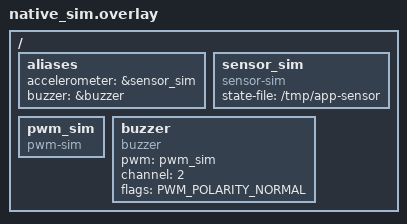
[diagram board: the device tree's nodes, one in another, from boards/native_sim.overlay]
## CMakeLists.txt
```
cmake_minimum_required(VERSION 3.20.0)

find_package(Zephyr REQUIRED HINTS $ENV{ZEPHYR_BASE})
project(workshop)

target_include_directories(app PRIVATE ${CMAKE_CURRENT_SOURCE_DIR}/src)

target_sources(app PRIVATE
    src/cpp_wrappers/ApplicationAssert.cpp
    src/drivers/buzzer.c
    src/frequency.c
    src/SensorReader.cpp
    src/BuzzerController.cpp
    src/main.cpp
)

if(CONFIG_ARCH_POSIX)
    target_sources(app PRIVATE 
        src/drivers/sensor_sim.c
        src/drivers/pwm_sim.c
    )
endif()
```

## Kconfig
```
menu "Application"

config APP_HELLO_WORLD_MSG
	string "Hello World Message"
	default "Hello World!"
	help
	  Customizable hello world message.

endmenu

source "Kconfig.zephyr"
```

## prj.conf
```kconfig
CONFIG_DEBUG=y
CONFIG_DEBUG_THREAD_INFO=y
#CONFIG_NO_OPTIMIZATIONS=y

CONFIG_LOG=y
CONFIG_LOG_MODE_DEFERRED=y
#CONFIG_LOG_MODE_IMMEDIATE=y

CONFIG_SHELL=y

CONFIG_I2C=y
#CONFIG_I2C_LOG_LEVEL_DBG=y
#CONFIG_I2C_DUMP_MESSAGES=y

CONFIG_SENSOR=y
CONFIG_SENSOR_SHELL=y
CONFIG_SENSOR_INFO=y
#CONFIG_SENSOR_LOG_LEVEL_DBG=y

CONFIG_PWM=y
CONFIG_PWM_SHELL=y
```

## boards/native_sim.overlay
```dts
#include <zephyr/dt-bindings/pwm/pwm.h>

/ {
	aliases {
		accelerometer = &sensor_sim;
		buzzer = &buzzer;
	};

	sensor_sim: sensor_sim {
		compatible = "sensor-sim";
		state-file = "/tmp/app-sensor";
		status = "okay";
	};

	pwm_sim: pwm_sim {
		compatible = "pwm-sim";
		status = "okay";
	};

	buzzer: buzzer {
		compatible = "buzzer";
		pwm = <&pwm_sim>;
		channel = <2>;
		flags = <PWM_POLARITY_NORMAL>;
		status = "okay";
	};
};
```

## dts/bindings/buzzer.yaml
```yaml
description: |
  Demonstration of a simple driver to control a buzzer.

compatible: "buzzer"

properties:
  pwm:
    type: phandle
    required: true
    description: |
      PWM to be used for the buzzer.
  
  channel:
    type: int
    required: true

  flags:
    type: int
    required: true
```

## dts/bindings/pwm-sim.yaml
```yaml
description: |
  Simulated PWM output.

compatible: "pwm-sim"
```

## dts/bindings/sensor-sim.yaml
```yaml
description: |
  Simulated sensor.

compatible: "sensor-sim"

properties:
  state-file:
    type: string
    required: true
```

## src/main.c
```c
#include <zephyr/kernel.h>
#include <zephyr/logging/log.h>
#include <zephyr/drivers/sensor.h>
#include "drivers/buzzer.h"
#include "frequency.h"

#define PWM_CHANNEL 2

LOG_MODULE_REGISTER(main);

static void sensor_timer_callback(struct k_timer *timer);
static void sensor_thread_function(void *p1, void *p2, void *p3);
static void buzzer_thread_function(void *p1, void *p2, void *p3);

K_TIMER_DEFINE(sensor_timer, sensor_timer_callback, NULL);
K_SEM_DEFINE(sensor_sem, 0, 1);
K_THREAD_DEFINE(sensor_thread, 1024, sensor_thread_function, NULL, NULL, NULL, 5, 0, 0);
K_MSGQ_DEFINE(message_queue, sizeof(struct sensor_value), 3, 1);
K_THREAD_DEFINE(buzzer_thread, 1024, buzzer_thread_function, NULL, NULL, NULL, 5, 0, 0);

int main(void)
{
    LOG_INF("%s %s", CONFIG_APP_HELLO_WORLD_MSG, CONFIG_BOARD_TARGET);

    k_timer_start(&sensor_timer, K_MSEC(20), K_MSEC(20));

    return 0;
}

static void sensor_timer_callback(struct k_timer *timer)
{
    ARG_UNUSED(timer);

    k_sem_give(&sensor_sem);
}

static void sensor_thread_function(void *p1, void *p2, void *p3)
{
    ARG_UNUSED(p1);
    ARG_UNUSED(p2);
    ARG_UNUSED(p3);

    const struct device* sensor_dev = DEVICE_DT_GET(DT_ALIAS(accelerometer));
    struct sensor_value accel_z;
    int ret = 0;

    while (true) {
        k_sem_take(&sensor_sem, K_FOREVER);

        ret = sensor_sample_fetch(sensor_dev);

        if (ret != 0) {
            LOG_ERR("sensor_sample_fetch: %d", ret);
            continue;
        }

        ret = sensor_channel_get(sensor_dev, SENSOR_CHAN_ACCEL_Z, &accel_z);

        if (ret != 0) {
            LOG_ERR("sensor_channel_get: %d", ret);
            continue;
        }

        ret = k_msgq_put(&message_queue, &accel_z, K_NO_WAIT);

        if (ret != 0) {
            LOG_WRN("k_msgq_put: %d", ret);
        }
    }
}

static void buzzer_thread_function(void *p1, void *p2, void *p3)
{
    ARG_UNUSED(p1);
    ARG_UNUSED(p2);
    ARG_UNUSED(p3);

    const struct device* buzzer_dev = DEVICE_DT_GET(DT_ALIAS(buzzer));
    struct sensor_value accel_z;
    int ret = 0;

    while (true) {
        ret = k_msgq_get(&message_queue, &accel_z, K_FOREVER);

        if (ret != 0) {
            LOG_ERR("k_msgq_get: %d", ret);
            continue;
        }

        const float value = sensor_value_to_float(&accel_z);
        const uint32_t freq = accel_to_freq(value);

        if (freq == 0) {
            ret = buzzer_disable(buzzer_dev);
        } else {
            ret = buzzer_enable(buzzer_dev, freq);
        }

        if (ret != 0) {
            LOG_ERR("pwm_set: %d", ret);
        }
    }
}
```

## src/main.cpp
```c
#include "cpp_wrappers/Buzzer.hpp"
#include "cpp_wrappers/Accelerometer.hpp"
#include "cpp_wrappers/Thread.hpp"
#include "cpp_wrappers/SoftwareTimer.hpp"
#include "cpp_wrappers/MessageQueue.hpp"
#include "cpp_wrappers/Semaphore.hpp"
#include <zephyr/logging/log.h>
#include "frequency.h"

#define PWM_CHANNEL 2

LOG_MODULE_REGISTER(main);

static void sensor_timer_callback();
static void sensor_thread_function();
static void buzzer_thread_function();

K_THREAD_STACK_DEFINE(sensor_thread_stack, 1024);
K_THREAD_STACK_DEFINE(buzzer_thread_stack, 1024);

static Thread sensor_thread(sensor_thread_stack, K_THREAD_STACK_SIZEOF(sensor_thread_stack), sensor_thread_function, 5);
static Thread buzzer_thread(buzzer_thread_stack, K_THREAD_STACK_SIZEOF(buzzer_thread_stack), buzzer_thread_function, 5);

static SoftwareTimer sensor_timer(sensor_timer_callback);
static Semaphore sensor_sem(0, 1);
static MessageQueue<float, 3> message_queue;

static Accelerometer accelerometer(DEVICE_DT_GET(DT_ALIAS(accelerometer)));
static Buzzer buzzer(DEVICE_DT_GET(DT_ALIAS(buzzer)));

extern "C" int main(void)
{
    LOG_INF("%s %s", CONFIG_APP_HELLO_WORLD_MSG, CONFIG_BOARD_TARGET);

    sensor_thread.start();
    buzzer_thread.start();

    sensor_timer.start(std::chrono::milliseconds(20));

    return 0;
}

static void sensor_timer_callback()
{
    sensor_sem.give();
}

static void sensor_thread_function()
{
    while (true) {
        sensor_sem.take();
        const float value = accelerometer.read();
        message_queue.put(value);
    }
}

static void buzzer_thread_function()
{
    while (true) {
        const float value = message_queue.get();
        const uint32_t freq = accel_to_freq(value);

        if (freq == 0) {
            buzzer.disable();
        } else {
            buzzer.enable(freq);
        }
    }
}
```

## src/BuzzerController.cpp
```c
#include "BuzzerController.hpp"
#include "frequency.h"

BuzzerController::BuzzerController(Thread &thread, 
                                   MessageQueue<float> &message_queue, 
                                   IBuzzer &buzzer) :
    _thread(thread),
    _message_queue(message_queue),
    _buzzer(buzzer)
{
}

void BuzzerController::start()
{
    _thread.start([this] { thread_main(); });
}

void BuzzerController::thread_main()
{
    while (true) {
        const float value = _message_queue.get();
        const uint32_t freq = accel_to_freq(value);

        if (freq == 0) {
            _buzzer.disable();
        } else {
            _buzzer.enable(freq);
        }
    }
}
```

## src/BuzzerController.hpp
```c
#pragma once

#include "cpp_wrappers/Thread.hpp"
#include "cpp_wrappers/SoftwareTimer.hpp"
#include "cpp_wrappers/Semaphore.hpp"
#include "cpp_wrappers/MessageQueue.hpp"
#include "cpp_wrappers/Buzzer.hpp"

class BuzzerController
{
public:
    BuzzerController(Thread &thread, MessageQueue<float> &message_queue, Buzzer &Buzzer);

    void start();

    BuzzerController(const BuzzerController &) = delete;
    BuzzerController &operator=(const BuzzerController &) = delete;
    BuzzerController(BuzzerController &&) = delete;
    BuzzerController &operator=(BuzzerController &&) = delete;

private:
    Thread &_thread;
    MessageQueue<float> &_message_queue;
    Buzzer &_buzzer;

    void thread_main();
};
```

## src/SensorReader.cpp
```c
#include "SensorReader.hpp"

SensorReader::SensorReader(Thread &thread, MessageQueue<float> &message_queue, Accelerometer &accelerometer) : 
    _thread(thread),
    _message_queue(message_queue),
    _accelerometer(accelerometer),
    _timer([this] { timer_callback(); }),
    _semaphore(0, 1)
{
}

void SensorReader::start()
{
    _thread.start([this] { thread_main(); });
    _timer.start(std::chrono::milliseconds(20));
}

void SensorReader::timer_callback()
{
    _semaphore.give();
}

void SensorReader::thread_main()
{
    while (true) {
        _semaphore.take();
        const float value = _accelerometer.read();
        _message_queue.put(value);
    }
}
```

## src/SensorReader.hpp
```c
#pragma once

#include "cpp_wrappers/Thread.hpp"
#include "cpp_wrappers/SoftwareTimer.hpp"
#include "cpp_wrappers/Semaphore.hpp"
#include "cpp_wrappers/MessageQueue.hpp"
#include "cpp_wrappers/Accelerometer.hpp"

class SensorReader
{
public:
    SensorReader(Thread &thread, MessageQueue<float> &message_queue, Accelerometer &accelerometer);

    void start();

    SensorReader(const SensorReader &) = delete;
    SensorReader &operator=(const SensorReader &) = delete;
    SensorReader(SensorReader &&) = delete;
    SensorReader &operator=(SensorReader &&) = delete;

private:
    Thread &_thread;
    MessageQueue<float> &_message_queue;
    Accelerometer &_accelerometer;

    SoftwareTimer _timer;
    Semaphore _semaphore;

    void timer_callback();
    void thread_main();
};
```

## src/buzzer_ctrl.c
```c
#include "buzzer_ctrl.h"
#include "drivers/buzzer.h"
#include <zephyr/logging/log.h>

LOG_MODULE_REGISTER(buzzer_ctrl);

static void buzzer_thread_function(void *p1, void *p2, void *p3);

K_MSGQ_DEFINE(buzzer_msgq, sizeof(int), 3, 1);
K_THREAD_DEFINE(buzzer_thread, 1024, buzzer_thread_function, NULL, NULL, NULL, 5, 0, 0);

void buzzer_ctrl_post(const struct sensor_value *accel_z)
{
    int ret = k_msgq_put(&buzzer_msgq, accel_z, K_NO_WAIT);

    if (ret != 0) {
        LOG_WRN("k_msgq_put: %d", ret);
    }
}

static void buzzer_thread_function(void *p1, void *p2, void *p3)
{
    ARG_UNUSED(p1);
    ARG_UNUSED(p2);
    ARG_UNUSED(p3);

    const struct device *buzzer_dev = DEVICE_DT_GET(DT_CHOSEN(workshop_buzzer));
    struct sensor_value accel_z;
    int ret = 0;

    while (true) {
        ret = k_msgq_get(&buzzer_msgq, &accel_z, K_FOREVER);

        if (ret != 0) {
            LOG_ERR("k_msgq_get: %d", ret);
            continue;
        }

        buzzer_enable(buzzer_dev, accel_z.val1 < 9);
    }
}
```

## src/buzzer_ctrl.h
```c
#pragma once

#include <zephyr/drivers/sensor.h>

void buzzer_ctrl_post(const struct sensor_value* accel_z);
```

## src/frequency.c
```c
#include "frequency.h"

#define MIN_FREQ   500.0f
#define MAX_FREQ   3000.0f
#define MIN_ACCEL  8.0f
#define MAX_ACCEL  -9.0f

uint32_t accel_to_freq(float accel)
{
    if (accel > MIN_ACCEL) {
        return 0;
    }

    float freq = MIN_FREQ + (accel - MIN_ACCEL) * (MAX_FREQ - MIN_FREQ) / (MAX_ACCEL - MIN_ACCEL);
    return (uint32_t)freq;
}
```

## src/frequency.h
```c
#ifndef FREQUENCY_H
#define FREQUENCY_H

#include <stdint.h>

#ifdef __cplusplus
extern "C" {
#endif

/**
 * Map an acceleration value to a buzzer frequency in Hz.
 *
 * Returns 0 when the buzzer should be off (accel > 8.0).
 * Otherwise returns a value linearly interpolated in [500, 3000] Hz
 * for accel in [8.0, -9.0].
 */
uint32_t accel_to_freq(float accel);

#ifdef __cplusplus
}
#endif

#endif /* FREQUENCY_H */
```

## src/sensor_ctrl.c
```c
#include "sensor_ctrl.h"
#include "buzzer_ctrl.h"
#include <zephyr/kernel.h>
#include <zephyr/logging/log.h>
#include <zephyr/drivers/sensor.h>

LOG_MODULE_REGISTER(sensor_ctrl);

static void sensor_timer_callback(struct k_timer *timer);
static void sensor_thread_function(void *p1, void *p2, void *p3);

K_TIMER_DEFINE(sensor_timer, sensor_timer_callback, NULL);
K_SEM_DEFINE(sensor_sem, 0, 1);
K_THREAD_DEFINE(sensor_thread, 1024, sensor_thread_function, NULL, NULL, NULL, 5, 0, 0);

void sensor_ctrl_start(void)
{
    k_timer_start(&sensor_timer, K_MSEC(10), K_MSEC(10));
}

static void sensor_timer_callback(struct k_timer *timer)
{
    ARG_UNUSED(timer);

    k_sem_give(&sensor_sem);
}

static void sensor_thread_function(void *p1, void *p2, void *p3)
{
    ARG_UNUSED(p1);
    ARG_UNUSED(p2);
    ARG_UNUSED(p3);

    const struct device *sensor_dev = DEVICE_DT_GET(DT_CHOSEN(workshop_sensor));
    struct sensor_value accel_z;
    int ret = 0;

    while (true) {
        k_sem_take(&sensor_sem, K_FOREVER);

        ret = sensor_sample_fetch(sensor_dev);

        if (ret != 0) {
            LOG_ERR("sensor_sample_fetch: %d", ret);
            continue;
        }

        ret = sensor_channel_get(sensor_dev, SENSOR_CHAN_ACCEL_Z, &accel_z);

        if (ret != 0) {
            LOG_ERR("sensor_channel_get: %d", ret);
            continue;
        }

        buzzer_ctrl_post(&accel_z);
    }
}
```

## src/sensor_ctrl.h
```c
#pragma once

void sensor_ctrl_start(void);
```
